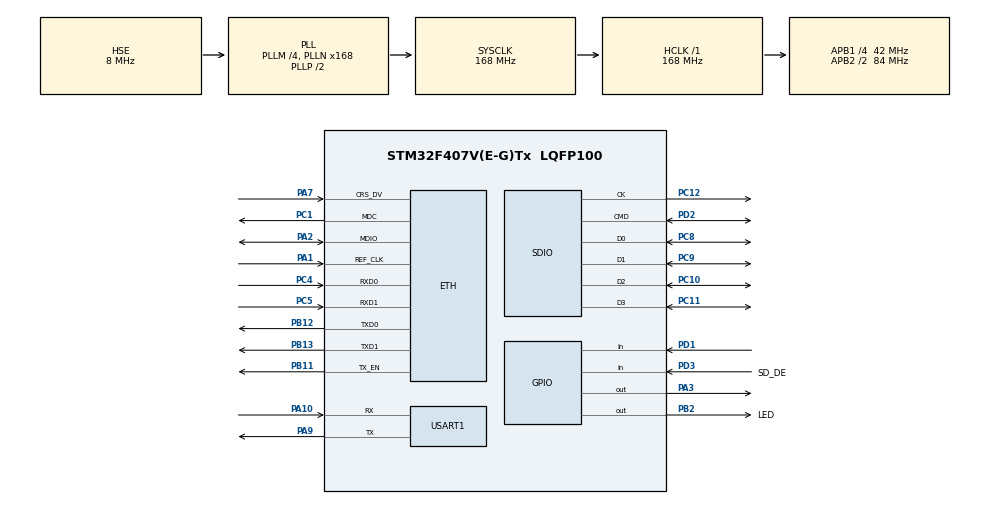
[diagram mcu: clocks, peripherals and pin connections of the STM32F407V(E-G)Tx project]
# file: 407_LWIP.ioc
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Dma.Request0=SDIO
Dma.SDIO.0.Direction=DMA_PERIPH_TO_MEMORY
Dma.SDIO.0.FIFOMode=DMA_FIFOMODE_ENABLE
Dma.SDIO.0.FIFOThreshold=DMA_FIFO_THRESHOLD_FULL
Dma.SDIO.0.Instance=DMA2_Stream3
Dma.SDIO.0.MemBurst=DMA_MBURST_INC4
Dma.SDIO.0.MemDataAlignment=DMA_MDATAALIGN_WORD
Dma.SDIO.0.MemInc=DMA_MINC_ENABLE
Dma.SDIO.0.Mode=DMA_PFCTRL
Dma.SDIO.0.PeriphBurst=DMA_PBURST_INC4
Dma.SDIO.0.PeriphDataAlignment=DMA_PDATAALIGN_WORD
Dma.SDIO.0.PeriphInc=DMA_PINC_DISABLE
Dma.SDIO.0.Priority=DMA_PRIORITY_LOW
ETH.AutoNegotiation=ETH_AUTONEGOTIATION_ENABLE
ETH.MACAddr=00\:80\:E1\:00\:00\:00
ETH.MediaInterface=ETH_MEDIA_INTERFACE_RMII
ETH.PHY_DUPLEX_STATUS=0x0010
ETH.PHY_Name_RMII=userPHY
ETH.PHY_SPEED_STATUS=0x0004
ETH.PHY_SR=0x1F
ETH.PHY_User_Name=LAN8720A
ETH.PhyAddress=0
FATFS.BSP.number=1
FATFS._CODE_PAGE=936
FATFS._USE_LFN=2
FATFS._VOLUMES=2
FATFS0.BSP.STBoard=false
FATFS0.BSP.api=Unknown
FATFS0.BSP.i2caddr=0
FATFS0.BSP.instance=PD1
FATFS0.BSP.ip=GPIO
FATFS0.BSP.mode=Input
FATFS0.BSP.name=Detect_SDIO
FATFS0.BSP.solution=PD1
FREERTOS.Tasks01=defaultTask,24,128,StartDefaultTask,Default,NULL,Dynamic,NULL,NULL
LWIP.GATEWAY_ADDRESS=192.168.001.001
LWIP.IP_ADDRESS=192.168.001.233
LWIP.LWIP_DHCP=0
LWIP.LWIP_HTTPD=0
LWIP.LWIP_NETIF_STATUS_CALLBACK=1
LWIP.NETMASK_ADDRESS=255.255.255.000
LWIP.Version=v2.1.2_Cube
Mcu.Family=STM32F4
Mcu.Name=STM32F407V(E-G)Tx
Mcu.Package=LQFP100
NVIC.DMA2_Stream3_IRQn=true\:6\:0\:true\:false\:true\:true\:false\:true
NVIC.ETH_IRQn=true\:5\:0\:false\:false\:true\:true\:false\:true
NVIC.PriorityGroup=NVIC_PRIORITYGROUP_4
NVIC.SDIO_IRQn=true\:5\:0\:false\:false\:true\:true\:true\:true
PA1.Mode=RMII
PA1.Signal=ETH_REF_CLK
PA10.Mode=Asynchronous
PA10.Signal=USART1_RX
PA13.Mode=Serial_Wire
PA13.Signal=SYS_JTMS-SWDIO
PA14.Mode=Serial_Wire
PA14.Signal=SYS_JTCK-SWCLK
PA2.Mode=RMII
PA2.Signal=ETH_MDIO
PA3.GPIO_PuPd=GPIO_PULLUP
PA3.PinState=GPIO_PIN_SET
PA3.Signal=GPIO_Output
PA7.Mode=RMII
PA7.Signal=ETH_CRS_DV
PA9.Mode=Asynchronous
PA9.Signal=USART1_TX
PB11.Mode=RMII
PB11.Signal=ETH_TX_EN
PB12.Mode=RMII
PB12.Signal=ETH_TXD0
PB13.Mode=RMII
PB13.Signal=ETH_TXD1
PB2.GPIO_Label=LED
PB2.GPIO_PuPd=GPIO_PULLUP
PB2.Signal=GPIO_Output
PC1.Mode=RMII
PC1.Signal=ETH_MDC
PC10.Mode=SD_4_bits_Wide_bus
PC10.Signal=SDIO_D2
PC11.Mode=SD_4_bits_Wide_bus
PC11.Signal=SDIO_D3
PC12.Mode=SD_4_bits_Wide_bus
PC12.Signal=SDIO_CK
PC4.Mode=RMII
PC4.Signal=ETH_RXD0
PC5.Mode=RMII
PC5.Signal=ETH_RXD1
PC8.Mode=SD_4_bits_Wide_bus
PC8.Signal=SDIO_D0
PC9.Mode=SD_4_bits_Wide_bus
PC9.Signal=SDIO_D1
PD1.Signal=GPIO_Input
PD2.Mode=SD_4_bits_Wide_bus
PD2.Signal=SDIO_CMD
PD3.GPIO_Label=SD_DE
PD3.GPIO_PuPd=GPIO_PULLUP
PD3.Signal=GPIO_Input
PH0-OSC_IN.Mode=HSE-External-Oscillator
PH0-OSC_IN.Signal=RCC_OSC_IN
PH1-OSC_OUT.Mode=HSE-External-Oscillator
PH1-OSC_OUT.Signal=RCC_OSC_OUT
ProjectManager.HeapSize=0x200
ProjectManager.StackSize=0x1000
ProjectManager.TargetToolchain=MDK-ARM V5.27
RCC.48MHZClocksFreq_Value=48000000
RCC.AHBFreq_Value=168000000
RCC.APB1CLKDivider=RCC_HCLK_DIV4
RCC.APB1Freq_Value=42000000
RCC.APB1TimFreq_Value=84000000
RCC.APB2CLKDivider=RCC_HCLK_DIV2
RCC.APB2Freq_Value=84000000
RCC.APB2TimFreq_Value=168000000
RCC.CortexFreq_Value=168000000
RCC.HCLKFreq_Value=168000000
RCC.HSE_VALUE=8000000
RCC.HSI_VALUE=16000000
RCC.LSE_VALUE=32768
RCC.PLLM=4
RCC.PLLN=168
RCC.PLLQ=7
RCC.PLLSourceVirtual=RCC_PLLSOURCE_HSE
RCC.SYSCLKFreq_VALUE=168000000
RCC.SYSCLKSource=RCC_SYSCLKSOURCE_PLLCLK
RCC.VCOOutputFreq_Value=336000000
USART1.VirtualMode=VM_ASYNC
VP_FATFS_VS_SDIO.Mode=SDIO
VP_FREERTOS_VS_CMSIS_V2.Mode=CMSIS_V2
VP_LWIP_VS_Enabled.Mode=Enabled
board=custom

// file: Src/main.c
/* USER CODE BEGIN Header */
/**
  ******************************************************************************
  * @file           : main.c
  * @brief          : Main program body
  ******************************************************************************
  * @attention
  *
  * <h2><center>&copy; Copyright (c) 2025 STMicroelectronics.
  * All rights reserved.</center></h2>
  *
  * This software component is licensed by ST under Ultimate Liberty license
  * SLA0044, the "License"; You may not use this file except in compliance with
  * the License. You may obtain a copy of the License at:
  *                             www.st.com/SLA0044
  *
  ******************************************************************************
  */
/* USER CODE END Header */
#include "main.h"
#include "cmsis_os.h"
#include "dma.h"
#include "fatfs.h"
#include "lwip.h"
#include "sdio.h"
#include "usart.h"
#include "gpio.h"

void SystemClock_Config(void);
void MX_FREERTOS_Init(void);
/* USER CODE BEGIN PFP */
extern struct netif gnetif;
struct dhcp *dhcp;
/* USER CODE END PFP */

int main(void)
{

  /* MCU Configuration--------------------------------------------------------*/

  /* Reset of all peripherals, Initializes the Flash interface and the Systick. */
  HAL_Init();

  /* Configure the system clock */
  SystemClock_Config();

  /* Initialize all configured peripherals */
  MX_GPIO_Init();
  MX_DMA_Init();
  MX_USART1_UART_Init();
  MX_SDIO_SD_Init();
  MX_FATFS_Init();
  /* USER CODE BEGIN 2 */
  HAL_GPIO_WritePin(GPIOA, GPIO_PIN_3, GPIO_PIN_RESET);
  HAL_Delay(100);
  HAL_GPIO_WritePin(GPIOA, GPIO_PIN_3, GPIO_PIN_SET);
  /* USER CODE END 2 */

  /* Init scheduler */
  osKernelInitialize();  /* Call init function for freertos objects (in freertos.c) */
  MX_FREERTOS_Init();
  /* Start scheduler */
  osKernelStart();

  /* We should never get here as control is now taken by the scheduler */
  /* Infinite loop */
  while (1)
  {

  }
}

void SystemClock_Config(void)
{
  RCC_OscInitTypeDef RCC_OscInitStruct = {0};
  RCC_ClkInitTypeDef RCC_ClkInitStruct = {0};

  /** Configure the main internal regulator output voltage
  */
  __HAL_RCC_PWR_CLK_ENABLE();
  __HAL_PWR_VOLTAGESCALING_CONFIG(PWR_REGULATOR_VOLTAGE_SCALE1);
  /** Initializes the RCC Oscillators according to the specified parameters
  * in the RCC_OscInitTypeDef structure.
  */
  RCC_OscInitStruct.OscillatorType = RCC_OSCILLATORTYPE_HSE;
  RCC_OscInitStruct.HSEState = RCC_HSE_ON;
  RCC_OscInitStruct.PLL.PLLState = RCC_PLL_ON;
  RCC_OscInitStruct.PLL.PLLSource = RCC_PLLSOURCE_HSE;
  RCC_OscInitStruct.PLL.PLLM = 4;
  RCC_OscInitStruct.PLL.PLLN = 168;
  RCC_OscInitStruct.PLL.PLLP = RCC_PLLP_DIV2;
  RCC_OscInitStruct.PLL.PLLQ = 7;
  if (HAL_RCC_OscConfig(&RCC_OscInitStruct) != HAL_OK)
  {
    Error_Handler();
  }
  /** Initializes the CPU, AHB and APB buses clocks
  */
  RCC_ClkInitStruct.ClockType = RCC_CLOCKTYPE_HCLK|RCC_CLOCKTYPE_SYSCLK
                              |RCC_CLOCKTYPE_PCLK1|RCC_CLOCKTYPE_PCLK2;
  RCC_ClkInitStruct.SYSCLKSource = RCC_SYSCLKSOURCE_PLLCLK;
  RCC_ClkInitStruct.AHBCLKDivider = RCC_SYSCLK_DIV1;
  RCC_ClkInitStruct.APB1CLKDivider = RCC_HCLK_DIV4;
  RCC_ClkInitStruct.APB2CLKDivider = RCC_HCLK_DIV2;

  if (HAL_RCC_ClockConfig(&RCC_ClkInitStruct, FLASH_LATENCY_5) != HAL_OK)
  {
    Error_Handler();
  }
}

void Error_Handler(void)
{
  __disable_irq();
  while (1)
  {
  }
}

/************************ (C) COPYRIGHT STMicroelectronics *****END OF FILE****/

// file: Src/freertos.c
/* USER CODE BEGIN Header */
/**
  ******************************************************************************
  * File Name          : freertos.c
  * Description        : Code for freertos applications
  ******************************************************************************
  * @attention
  *
  * <h2><center>&copy; Copyright (c) 2025 STMicroelectronics.
  * All rights reserved.</center></h2>
  *
  * This software component is licensed by ST under Ultimate Liberty license
  * SLA0044, the "License"; You may not use this file except in compliance with
  * the License. You may obtain a copy of the License at:
  *                             www.st.com/SLA0044
  *
  ******************************************************************************
  */
/* USER CODE END Header */

#include "FreeRTOS.h"
#include "task.h"
#include "main.h"
#include "cmsis_os.h"

/* USER CODE BEGIN Includes */
#include "lwip/sockets.h"
#include "lwip/sys.h"

#include "fatfs.h"

#include "stdio.h"
#include "string.h"

#include "httpServer.h"
/* USER CODE END Includes */

/* USER CODE BEGIN PM */
#define TCP_PORT 8080
#define MAX_BUFFER_SIZE 1024
#define MAX_CLIENTS 5  // �??????大客户端数量

#define MULTICAST_PORT_LOCAL 20001
#define MULTICAST_PORT_REMOTE 20002
#define MULTICAST_IP "226.0.0.80"

FATFS fs;                       /* FatFs 文件系统对象 */
/* USER CODE END PM */

/* Definitions for defaultTask */
osThreadId_t defaultTaskHandle;
const osThreadAttr_t defaultTask_attributes = {
  .name = "defaultTask",
  .stack_size = 128 * 4,
  .priority = (osPriority_t) osPriorityNormal,
};

/* USER CODE BEGIN FunctionPrototypes */
osThreadId_t tcpServerTaskHandle;
const osThreadAttr_t tcpServer_attributes = {
  .name = "tcpServerTask",
  .stack_size = 128 * 8,
  .priority = (osPriority_t) osPriorityBelowNormal5,
};
void StartTcpServerTask(void *argument);

osThreadId_t multicastTaskHandle;
const osThreadAttr_t multicast_attributes = {
  .name = "multicastTask",
  .stack_size = 128 * 8,
  .priority = (osPriority_t) osPriorityBelowNormal6,
};
void StartMulticastTask(void *argument);

// // SD TASK
// osThreadId_t sdTaskHandle;
// const osThreadAttr_t sdTask_attributes = {
//   .name = "sdTask",
//   .stack_size = 128 * 8,
//   .priority = (osPriority_t) osPriorityBelowNormal7,
// };
// void StartSdTask(void *argument);

// void http_request_handler(int socket, http_request_t *request);

void rainbow_handler(int socket, http_request_t *request);
void brightness_handler(int socket, http_request_t *request);
void random_handler(int socket, http_request_t *request);
void color_handler(int socket, http_request_t *request);
/* USER CODE END FunctionPrototypes */

void StartDefaultTask(void *argument);

extern void MX_LWIP_Init(void);
void MX_FREERTOS_Init(void); /* (MISRA C 2004 rule 8.1) */

void MX_FREERTOS_Init(void) {

  /* Create the thread(s) */
  /* creation of defaultTask */
  defaultTaskHandle = osThreadNew(StartDefaultTask, NULL, &defaultTask_attributes);

  /* USER CODE BEGIN RTOS_THREADS */
  /* add threads, ... */
  // tcpServerTaskHandle = osThreadNew(StartTcpServerTask, NULL, &tcpServer_attributes);
  // multicastTaskHandle = osThreadNew(StartMulticastTask, NULL, &multicast_attributes);

  // sdTaskHandle = osThreadNew(StartSdTask, NULL, &sdTask_attributes);

  // http_server_init(80);
  // // http_server_set_callback(http_request_handler);
  // http_register_route("/rainbow", rainbow_handler);
  // http_register_route("/brightness", brightness_handler);
  // http_register_route("/color", color_handler);
  // http_register_route("/random", random_handler);

  /* USER CODE END RTOS_THREADS */

}

void StartDefaultTask(void *argument)
{
  /* init code for LWIP */
  MX_LWIP_Init();
  /* USER CODE BEGIN StartDefaultTask */

  FRESULT f_res;
  f_res = f_mount(&fs, "0:", 1);
  if (f_res != FR_OK) {
    printf("Mount failed\r\n");
  } else {
    printf("Mount success\r\n");
  }

  // struct netif *netif = netif_default;

  // if (netif != NULL && netif_is_up(netif))
  // {
  //   printf("\r\nNetwork Parameters:");
  //   printf("\r\nIP Address: %s", ip4addr_ntoa(netif_ip4_addr(netif)));
  //   printf("\r\nSubnet Mask: %s", ip4addr_ntoa(netif_ip4_netmask(netif)));
  //   printf("\r\nGateway: %s", ip4addr_ntoa(netif_ip4_gw(netif)));
  //   printf("\r\nMAC Address: %02X-%02X-%02X-%02X-%02X-%02X\r\n",
  //          netif->hwaddr[0], netif->hwaddr[1], netif->hwaddr[2],
  //          netif->hwaddr[3], netif->hwaddr[4], netif->hwaddr[5]);
  // }else{
  //   printf("Network interface is down\r\n");
  // }
  /* Infinite loop */
  for(;;)
  {
    HAL_GPIO_TogglePin(LED_GPIO_Port, LED_Pin);
    // printf("Hello LWIP\r\n");
    osDelay(500);
  }
  /* USER CODE END StartDefaultTask */
}

/* USER CODE BEGIN Application */

// void StartTcpServerTask(void *argument)
// {
//   int server_fd;                       // 连接句柄
//   struct sockaddr_in server_addr, client_addr;    // 服务器和客户端地�??????
//   uint8_t rx_buffer[128];
//   socklen_t addr_len = sizeof(client_addr);

//   // 客户端管理数�??????
//   int client_sockets[MAX_CLIENTS] = {0};
//   fd_set readfds;
//   int max_sd, activity;

//   server_fd = socket(AF_INET, SOCK_STREAM, 0);    // 创建套接�??????
//   if (server_fd < 0)
//   {
//     printf("Create socket failed 1\r\n");
//     vTaskDelete(NULL);
//     return;
//   }

//   server_addr.sin_family = AF_INET;
//   server_addr.sin_port = htons(TCP_PORT);
//   server_addr.sin_addr.s_addr = INADDR_ANY;

//   if (bind(server_fd, (struct sockaddr *)&server_addr, sizeof(server_addr)) < 0)
//   {
//     printf("Bind failed\r\n");
//     vTaskDelete(NULL);
//     return;
//   }

//   if (listen(server_fd, MAX_CLIENTS) < 0)
//   {
//     printf("Socket listen failed\r\n");
//     closesocket(server_fd);
//     vTaskDelay(NULL);
//     return;
//   }
//   printf("TCP Server started on port %d\r\n", TCP_PORT);

//   while(1)
//   {

//     // 清空描述符集合并添加服务器socket
//     FD_ZERO(&readfds);
//     FD_SET(server_fd, &readfds);
//     max_sd = server_fd;

//     // 添加客户端socket到集�??????
//     for(int i = 0; i < MAX_CLIENTS; i++)
//     {
//       if(client_sockets[i] > 0)
//       {
//         FD_SET(client_sockets[i], &readfds);
//         if(client_sockets[i] > max_sd)
//           max_sd = client_sockets[i];
//       }
//     }

//     // 设置超时时间
//     struct timeval tv = {0, 10000}; // 10ms超时

//     // 等待事件发生
//     activity = select(max_sd + 1, &readfds, NULL, NULL, &tv);
//     if(activity < 0)
//     {
//       printf("Select error\r\n");
//       continue;
//     }

//     // �??????查是否有新的连接请求
//     if(FD_ISSET(server_fd, &readfds))
//     {
//       int new_socket = accept(server_fd, (struct sockaddr *)&server_addr, &addr_len);
//       if(new_socket < 0)
//       {
//         printf("Accept failed\r\n");
//         continue;
//       }

//       // 添加新的客户端socket到数�??????
//       for(int i = 0; i < MAX_CLIENTS; i++)
//       {
//         if(client_sockets[i] == 0)
//         {
//           client_sockets[i] = new_socket;
//           // 打印客户端IP地址和端�??????
//           printf("New client connected, IP: %s, Port: %d\r\n", inet_ntoa(server_addr.sin_addr), ntohs(server_addr.sin_port));
//           printf("New client connected, socket fd is %d\r\n", new_socket);
//           break;
//         }
//       }
//     }

//     // �??????查客户端数据
//     for(int i = 0; i < MAX_CLIENTS; i++)
//     {
//       if(client_sockets[i] > 0 && FD_ISSET(client_sockets[i], &readfds))
//       {
//         memset(rx_buffer, 0, sizeof(rx_buffer));
//         int rx_len = recv(client_sockets[i], rx_buffer, sizeof(rx_buffer), 0);

//         if(rx_len <= 0)
//         {
//           // 客户端断�??????连接
//           printf("Client disconnected, socket fd %d\r\n", client_sockets[i]);
//           closesocket(client_sockets[i]);
//           client_sockets[i] = 0;
//         }
//         else
//         {
//           // 处理接收到的数据
//           printf("From client %d: %s", i, rx_buffer);
//         }
//       }
//     }

//     osDelay(1);

//     // client_fd = accept(server_fd, (struct sockaddr *)&client_addr, &addr_len);
//     // if (client_fd < 0)
//     // {
//     //   printf("Socket accept failed\r\n");
//     //   continue;
//     // }

//     // printf("New client connected\r\n");

//     // while(1)
//     // {
//     //   memset(rx_buffer, 0, sizeof(rx_buffer));
//     //   int rx_len = recv(client_fd, rx_buffer, sizeof(rx_buffer), 0);
//     //   if (rx_len < 0)
//     //   {
//     //     printf("Client disconnected\r\n");
//     //     break;
//     //   }

//     //   printf("%s", rx_buffer);
//     // }
//     // closesocket(client_fd);
//   }
// }

// void StartMulticastTask(void *argument)
// {
//     int sock;
//     struct sockaddr_in local_addr, remote_addr;
//     struct ip_mreq mreq;
//     char rx_buffer[128];
//     char tx_buffer[] = "Multicast test message\r\n";

//     // 创建UDP套接�??????
//     sock = socket(AF_INET, SOCK_DGRAM, 0);
//     if (sock < 0) {
//         printf("Create multicast socket failed\r\n");
//         vTaskDelete(NULL);
//         return;
//     }

//     // 配置本地地址
//     memset(&local_addr, 0, sizeof(local_addr));
//     local_addr.sin_family = AF_INET;
//     local_addr.sin_port = htons(MULTICAST_PORT_LOCAL);
//     local_addr.sin_addr.s_addr = INADDR_ANY;

//     // 绑定socket到本地地�??????
//     if (bind(sock, (struct sockaddr*)&local_addr, sizeof(local_addr)) < 0) {
//         printf("Bind multicast socket failed\r\n");
//         closesocket(sock);
//         vTaskDelete(NULL);
//         return;
//     }

//     // 配置组播
//     mreq.imr_multiaddr.s_addr = inet_addr(MULTICAST_IP);
//     mreq.imr_interface.s_addr = INADDR_ANY;

//     // 加入组播�??????
//     if (setsockopt(sock, IPPROTO_IP, IP_ADD_MEMBERSHIP,
//                    (char *)&mreq, sizeof(mreq)) < 0) {
//         printf("Join multicast group failed\r\n");
//         closesocket(sock);
//         vTaskDelete(NULL);
//         return;
//     }

//     // 配置远程地址
//     memset(&remote_addr, 0, sizeof(remote_addr));
//     remote_addr.sin_family = AF_INET;
//     remote_addr.sin_port = htons(MULTICAST_PORT_REMOTE);
//     remote_addr.sin_addr.s_addr = inet_addr(MULTICAST_IP);

//     printf("Multicast task started\r\n");

//     while(1) {
//         fd_set readfds;
//         struct timeval tv = {0, 10000}; // 10ms超时

//         FD_ZERO(&readfds);
//         FD_SET(sock, &readfds);

//         // �??????查是否有数据可读
//         if (select(sock + 1, &readfds, NULL, NULL, &tv) > 0) {
//             if (FD_ISSET(sock, &readfds)) {
//                 // 接收数据
//                 memset(rx_buffer, 0, sizeof(rx_buffer));
//                 socklen_t addr_len = sizeof(remote_addr);
//                 int len = recvfrom(sock, rx_buffer, sizeof(rx_buffer)-1, 0,
//                                  (struct sockaddr*)&remote_addr, &addr_len);
//                 if (len > 0) {
//                     printf("Received multicast: %s\r\n", rx_buffer);
//                 }
//             }
//         }

//         // 每秒发�?�一次组播消�??????
//         static uint32_t last_send = 0;
//         uint32_t now = HAL_GetTick();
//         if (now - last_send >= 1000) {
//             sendto(sock, tx_buffer, strlen(tx_buffer), 0,
//                   (struct sockaddr*)&remote_addr, sizeof(remote_addr));
//             last_send = now;
//         }

//         osDelay(1);
//     }
// }

// void vAssertCalled(const char* file, int line)
// {
//     printf("Assert failed in %s:%d\r\n", file, line);

//     // 打印任务信息
//     TaskHandle_t currentTask = xTaskGetCurrentTaskHandle();
//     if (currentTask != NULL)
//     {
//         char *taskName = pcTaskGetName(currentTask);
//         printf("Current task: %s\r\n", taskName);

//         UBaseType_t stackHighWaterMark = uxTaskGetStackHighWaterMark(NULL);
//         printf("Stack high water mark: %lu\r\n", stackHighWaterMark);
//     }

//     // 打印�??????有任务状�??????
//     char *buffer = pvPortMalloc(2048);
//     if (buffer != NULL)
//     {
//         vTaskList(buffer);
//         printf("\r\nTask List:\r\n");
//         printf("Name          State  Priority  Stack   Num\r\n");
//         printf("*******************************************\r\n");
//         printf("%s\r\n", buffer);
//         vPortFree(buffer);
//     }
// }

void vAssertCalled(const char* file, int line)
{
    printf("Assert failed in %s:%d\r\n", file, line);

    // 打印当前任务信息
    TaskHandle_t currentTask = xTaskGetCurrentTaskHandle();
    if (currentTask != NULL)
    {
        char *taskName = pcTaskGetName(currentTask);
        printf("Current task: %s\r\n", taskName);

        // 打印堆栈使用情况
        UBaseType_t stackHighWaterMark = uxTaskGetStackHighWaterMark(NULL);
        printf("Stack high water mark: %lu words\r\n", stackHighWaterMark);
    }
    taskDISABLE_INTERRUPTS();
    for(;;);
}

// static const char index[] = {
//   0x3c, 0x21, 0x44, 0x4f, 0x43, 0x54, 0x59, 0x50, 0x45, 0x20, 0x68, 0x74, 0x6d, 0x6c, 0x3e, 0x0d,
//   0x0a, 0x3c, 0x68, 0x74, 0x6d, 0x6c, 0x3e, 0x0d, 0x0a, 0x3c, 0x68, 0x65, 0x61, 0x64, 0x3e, 0x0d,
//   0x0a, 0x20, 0x20, 0x20, 0x20, 0x3c, 0x6d, 0x65, 0x74, 0x61, 0x20, 0x63, 0x68, 0x61, 0x72, 0x73,
//   0x65, 0x74, 0x3d, 0x22, 0x55, 0x54, 0x46, 0x2d, 0x38, 0x22, 0x3e, 0x0d, 0x0a, 0x20, 0x20, 0x20,
//   0x20, 0x3c, 0x6d, 0x65, 0x74, 0x61, 0x20, 0x6e, 0x61, 0x6d, 0x65, 0x3d, 0x22, 0x76, 0x69, 0x65,
//   0x77, 0x70, 0x6f, 0x72, 0x74, 0x22, 0x20, 0x63, 0x6f, 0x6e, 0x74, 0x65, 0x6e, 0x74, 0x3d, 0x22,
//   0x77, 0x69, 0x64, 0x74, 0x68, 0x3d, 0x64, 0x65, 0x76, 0x69, 0x63, 0x65, 0x2d, 0x77, 0x69, 0x64,
//   0x74, 0x68, 0x2c, 0x20, 0x69, 0x6e, 0x69, 0x74, 0x69, 0x61, 0x6c, 0x2d, 0x73, 0x63, 0x61, 0x6c,
//   0x65, 0x3d, 0x31, 0x2e, 0x30, 0x22, 0x3e, 0x0d, 0x0a, 0x20, 0x20, 0x20, 0x20, 0x3c, 0x74, 0x69,
//   0x74, 0x6c, 0x65, 0x3e, 0x4c, 0x45, 0x44, 0xe6, 0x8e, 0xa7, 0xe5, 0x88, 0xb6, 0x3c, 0x2f, 0x74,
//   0x69, 0x74, 0x6c, 0x65, 0x3e, 0x0d, 0x0a, 0x20, 0x20, 0x20, 0x20, 0x3c, 0x73, 0x74, 0x79, 0x6c,
//   0x65, 0x3e, 0x0d, 0x0a, 0x20, 0x20, 0x20, 0x20, 0x20, 0x20, 0x20, 0x20, 0x62, 0x6f, 0x64, 0x79,
//   0x20, 0x7b, 0x20, 0x0d, 0x0a, 0x20, 0x20, 0x20, 0x20, 0x20, 0x20, 0x20, 0x20, 0x20, 0x20, 0x20,
//   0x20, 0x74, 0x65, 0x78, 0x74, 0x2d, 0x61, 0x6c, 0x69, 0x67, 0x6e, 0x3a, 0x20, 0x63, 0x65, 0x6e,
//   0x74, 0x65, 0x72, 0x3b, 0x20, 0x0d, 0x0a, 0x20, 0x20, 0x20, 0x20, 0x20, 0x20, 0x20, 0x20, 0x20,
//   0x20, 0x20, 0x20, 0x66, 0x6f, 0x6e, 0x74, 0x2d, 0x66, 0x61, 0x6d, 0x69, 0x6c, 0x79, 0x3a, 0x20,
//   0x41, 0x72, 0x69, 0x61, 0x6c, 0x3b, 0x20, 0x0d, 0x0a, 0x20, 0x20, 0x20, 0x20, 0x20, 0x20, 0x20,
//   0x20, 0x20, 0x20, 0x20, 0x20, 0x6d, 0x61, 0x78, 0x2d, 0x77, 0x69, 0x64, 0x74, 0x68, 0x3a, 0x20,
//   0x38, 0x30, 0x30, 0x70, 0x78, 0x3b, 0x0d, 0x0a, 0x20, 0x20, 0x20, 0x20, 0x20, 0x20, 0x20, 0x20,
//   0x20, 0x20, 0x20, 0x20, 0x6d, 0x61, 0x72, 0x67, 0x69, 0x6e, 0x3a, 0x20, 0x30, 0x20, 0x61, 0x75,
//   0x74, 0x6f, 0x3b, 0x0d, 0x0a, 0x20, 0x20, 0x20, 0x20, 0x20, 0x20, 0x20, 0x20, 0x20, 0x20, 0x20,
//   0x20, 0x70, 0x61, 0x64, 0x64, 0x69, 0x6e, 0x67, 0x3a, 0x20, 0x32, 0x30, 0x70, 0x78, 0x3b, 0x0d,
//   0x0a, 0x20, 0x20, 0x20, 0x20, 0x20, 0x20, 0x20, 0x20, 0x20, 0x20, 0x20, 0x20, 0x62, 0x61, 0x63,
//   0x6b, 0x67, 0x72, 0x6f, 0x75, 0x6e, 0x64, 0x2d, 0x63, 0x6f, 0x6c, 0x6f, 0x72, 0x3a, 0x20, 0x23,
//   0x66, 0x30, 0x66, 0x30, 0x66, 0x30, 0x3b, 0x0d, 0x0a, 0x20, 0x20, 0x20, 0x20, 0x20, 0x20, 0x20,
//   0x20, 0x7d, 0x0d, 0x0a, 0x20, 0x20, 0x20, 0x20, 0x20, 0x20, 0x20, 0x20, 0x2e, 0x63, 0x6f, 0x6e,
//   0x74, 0x61, 0x69, 0x6e, 0x65, 0x72, 0x20, 0x7b, 0x0d, 0x0a, 0x20, 0x20, 0x20, 0x20, 0x20, 0x20,
//   0x20, 0x20, 0x20, 0x20, 0x20, 0x20, 0x62, 0x61, 0x63, 0x6b, 0x67, 0x72, 0x6f, 0x75, 0x6e, 0x64,
//   0x2d, 0x63, 0x6f, 0x6c, 0x6f, 0x72, 0x3a, 0x20, 0x77, 0x68, 0x69, 0x74, 0x65, 0x3b, 0x0d, 0x0a,
//   0x20, 0x20, 0x20, 0x20, 0x20, 0x20, 0x20, 0x20, 0x20, 0x20, 0x20, 0x20, 0x70, 0x61, 0x64, 0x64,
//   0x69, 0x6e, 0x67, 0x3a, 0x20, 0x32, 0x30, 0x70, 0x78, 0x3b, 0x0d, 0x0a, 0x20, 0x20, 0x20, 0x20,
//   0x20, 0x20, 0x20, 0x20, 0x20, 0x20, 0x20, 0x20, 0x62, 0x6f, 0x72, 0x64, 0x65, 0x72, 0x2d, 0x72,
//   0x61, 0x64, 0x69, 0x75, 0x73, 0x3a, 0x20, 0x31, 0x30, 0x70, 0x78, 0x3b, 0x0d, 0x0a, 0x20, 0x20,
//   0x20, 0x20, 0x20, 0x20, 0x20, 0x20, 0x20, 0x20, 0x20, 0x20, 0x62, 0x6f, 0x78, 0x2d, 0x73, 0x68,
//   0x61, 0x64, 0x6f, 0x77, 0x3a, 0x20, 0x30, 0x20, 0x32, 0x70, 0x78, 0x20, 0x35, 0x70, 0x78, 0x20,
//   0x72, 0x67, 0x62, 0x61, 0x28, 0x30, 0x2c, 0x30, 0x2c, 0x30, 0x2c, 0x30, 0x2e, 0x31, 0x29, 0x3b,
//   0x0d, 0x0a, 0x20, 0x20, 0x20, 0x20, 0x20, 0x20, 0x20, 0x20, 0x7d, 0x0d, 0x0a, 0x20, 0x20, 0x20,
//   0x20, 0x20, 0x20, 0x20, 0x20, 0x2e, 0x63, 0x6f, 0x6c, 0x6f, 0x72, 0x50, 0x69, 0x63, 0x6b, 0x65,
//   0x72, 0x20, 0x7b, 0x20, 0x0d, 0x0a, 0x20, 0x20, 0x20, 0x20, 0x20, 0x20, 0x20, 0x20, 0x20, 0x20,
//   0x20, 0x20, 0x6d, 0x61, 0x72, 0x67, 0x69, 0x6e, 0x3a, 0x20, 0x32, 0x30, 0x70, 0x78, 0x3b, 0x0d,
//   0x0a, 0x20, 0x20, 0x20, 0x20, 0x20, 0x20, 0x20, 0x20, 0x20, 0x20, 0x20, 0x20, 0x77, 0x69, 0x64,
//   0x74, 0x68, 0x3a, 0x20, 0x31, 0x30, 0x30, 0x70, 0x78, 0x3b, 0x0d, 0x0a, 0x20, 0x20, 0x20, 0x20,
//   0x20, 0x20, 0x20, 0x20, 0x20, 0x20, 0x20, 0x20, 0x68, 0x65, 0x69, 0x67, 0x68, 0x74, 0x3a, 0x20,
//   0x35, 0x30, 0x70, 0x78, 0x3b, 0x0d, 0x0a, 0x20, 0x20, 0x20, 0x20, 0x20, 0x20, 0x20, 0x20, 0x7d,
//   0x0d, 0x0a, 0x20, 0x20, 0x20, 0x20, 0x20, 0x20, 0x20, 0x20, 0x2e, 0x62, 0x72, 0x69, 0x67, 0x68,
//   0x74, 0x6e, 0x65, 0x73, 0x73, 0x2d, 0x63, 0x6f, 0x6e, 0x74, 0x72, 0x6f, 0x6c, 0x20, 0x7b, 0x0d,
//   0x0a, 0x20, 0x20, 0x20, 0x20, 0x20, 0x20, 0x20, 0x20, 0x20, 0x20, 0x20, 0x20, 0x6d, 0x61, 0x72,
//   0x67, 0x69, 0x6e, 0x3a, 0x20, 0x32, 0x30, 0x70, 0x78, 0x3b, 0x0d, 0x0a, 0x20, 0x20, 0x20, 0x20,
//   0x20, 0x20, 0x20, 0x20, 0x20, 0x20, 0x20, 0x20, 0x77, 0x69, 0x64, 0x74, 0x68, 0x3a, 0x20, 0x38,
//   0x30, 0x25, 0x3b, 0x0d, 0x0a, 0x20, 0x20, 0x20, 0x20, 0x20, 0x20, 0x20, 0x20, 0x20, 0x20, 0x20,
//   0x20, 0x6d, 0x61, 0x78, 0x2d, 0x77, 0x69, 0x64, 0x74, 0x68, 0x3a, 0x20, 0x33, 0x30, 0x30, 0x70,
//   0x78, 0x3b, 0x0d, 0x0a, 0x20, 0x20, 0x20, 0x20, 0x20, 0x20, 0x20, 0x20, 0x20, 0x20, 0x20, 0x20,
//   0x64, 0x69, 0x73, 0x70, 0x6c, 0x61, 0x79, 0x3a, 0x20, 0x69, 0x6e, 0x6c, 0x69, 0x6e, 0x65, 0x2d,
//   0x62, 0x6c, 0x6f, 0x63, 0x6b, 0x3b, 0x0d, 0x0a, 0x20, 0x20, 0x20, 0x20, 0x20, 0x20, 0x20, 0x20,
//   0x7d, 0x0d, 0x0a, 0x20, 0x20, 0x20, 0x20, 0x20, 0x20, 0x20, 0x20, 0x2e, 0x73, 0x6c, 0x69, 0x64,
//   0x65, 0x72, 0x20, 0x7b, 0x0d, 0x0a, 0x20, 0x20, 0x20, 0x20, 0x20, 0x20, 0x20, 0x20, 0x20, 0x20,
//   0x20, 0x20, 0x77, 0x69, 0x64, 0x74, 0x68, 0x3a, 0x20, 0x31, 0x30, 0x30, 0x25, 0x3b, 0x0d, 0x0a,
//   0x20, 0x20, 0x20, 0x20, 0x20, 0x20, 0x20, 0x20, 0x20, 0x20, 0x20, 0x20, 0x68, 0x65, 0x69, 0x67,
//   0x68, 0x74, 0x3a, 0x20, 0x32, 0x35, 0x70, 0x78, 0x3b, 0x0d, 0x0a, 0x20, 0x20, 0x20, 0x20, 0x20,
//   0x20, 0x20, 0x20, 0x20, 0x20, 0x20, 0x20, 0x6d, 0x61, 0x72, 0x67, 0x69, 0x6e, 0x3a, 0x20, 0x31,
//   0x30, 0x70, 0x78, 0x20, 0x30, 0x3b, 0x0d, 0x0a, 0x20, 0x20, 0x20, 0x20, 0x20, 0x20, 0x20, 0x20,
//   0x7d, 0x0d, 0x0a, 0x20, 0x20, 0x20, 0x20, 0x20, 0x20, 0x20, 0x20, 0x62, 0x75, 0x74, 0x74, 0x6f,
//   0x6e, 0x20, 0x7b, 0x20, 0x0d, 0x0a, 0x20, 0x20, 0x20, 0x20, 0x20, 0x20, 0x20, 0x20, 0x20, 0x20,
//   0x20, 0x20, 0x70, 0x61, 0x64, 0x64, 0x69, 0x6e, 0x67, 0x3a, 0x20, 0x31, 0x32, 0x70, 0x78, 0x20,
//   0x32, 0x34, 0x70, 0x78, 0x3b, 0x0d, 0x0a, 0x20, 0x20, 0x20, 0x20, 0x20, 0x20, 0x20, 0x20, 0x20,
//   0x20, 0x20, 0x20, 0x6d, 0x61, 0x72, 0x67, 0x69, 0x6e, 0x3a, 0x20, 0x38, 0x70, 0x78, 0x3b, 0x0d,
//   0x0a, 0x20, 0x20, 0x20, 0x20, 0x20, 0x20, 0x20, 0x20, 0x20, 0x20, 0x20, 0x20, 0x62, 0x6f, 0x72,
//   0x64, 0x65, 0x72, 0x3a, 0x20, 0x6e, 0x6f, 0x6e, 0x65, 0x3b, 0x0d, 0x0a, 0x20, 0x20, 0x20, 0x20,
//   0x20, 0x20, 0x20, 0x20, 0x20, 0x20, 0x20, 0x20, 0x62, 0x6f, 0x72, 0x64, 0x65, 0x72, 0x2d, 0x72,
//   0x61, 0x64, 0x69, 0x75, 0x73, 0x3a, 0x20, 0x35, 0x70, 0x78, 0x3b, 0x0d, 0x0a, 0x20, 0x20, 0x20,
//   0x20, 0x20, 0x20, 0x20, 0x20, 0x20, 0x20, 0x20, 0x20, 0x63, 0x75, 0x72, 0x73, 0x6f, 0x72, 0x3a,
//   0x20, 0x70, 0x6f, 0x69, 0x6e, 0x74, 0x65, 0x72, 0x3b, 0x0d, 0x0a, 0x20, 0x20, 0x20, 0x20, 0x20,
//   0x20, 0x20, 0x20, 0x20, 0x20, 0x20, 0x20, 0x66, 0x6f, 0x6e, 0x74, 0x2d, 0x73, 0x69, 0x7a, 0x65,
//   0x3a, 0x20, 0x31, 0x36, 0x70, 0x78, 0x3b, 0x0d, 0x0a, 0x20, 0x20, 0x20, 0x20, 0x20, 0x20, 0x20,
//   0x20, 0x20, 0x20, 0x20, 0x20, 0x74, 0x72, 0x61, 0x6e, 0x73, 0x69, 0x74, 0x69, 0x6f, 0x6e, 0x3a,
//   0x20, 0x61, 0x6c, 0x6c, 0x20, 0x30, 0x2e, 0x33, 0x73, 0x20, 0x65, 0x61, 0x73, 0x65, 0x3b, 0x0d,
//   0x0a, 0x20, 0x20, 0x20, 0x20, 0x20, 0x20, 0x20, 0x20, 0x7d, 0x0d, 0x0a, 0x20, 0x20, 0x20, 0x20,
//   0x20, 0x20, 0x20, 0x20, 0x62, 0x75, 0x74, 0x74, 0x6f, 0x6e, 0x3a, 0x68, 0x6f, 0x76, 0x65, 0x72,
//   0x20, 0x7b, 0x0d, 0x0a, 0x20, 0x20, 0x20, 0x20, 0x20, 0x20, 0x20, 0x20, 0x20, 0x20, 0x20, 0x20,
//   0x74, 0x72, 0x61, 0x6e, 0x73, 0x66, 0x6f, 0x72, 0x6d, 0x3a, 0x20, 0x73, 0x63, 0x61, 0x6c, 0x65,
//   0x28, 0x31, 0x2e, 0x30, 0x35, 0x29, 0x3b, 0x0d, 0x0a, 0x20, 0x20, 0x20, 0x20, 0x20, 0x20, 0x20,
//   0x20, 0x7d, 0x0d, 0x0a, 0x20, 0x20, 0x20, 0x20, 0x20, 0x20, 0x20, 0x20, 0x2e, 0x62, 0x74, 0x6e,
//   0x2d, 0x63, 0x6f, 0x6c, 0x6f, 0x72, 0x20, 0x7b, 0x20, 0x62, 0x61, 0x63, 0x6b, 0x67, 0x72, 0x6f,
//   0x75, 0x6e, 0x64, 0x2d, 0x63, 0x6f, 0x6c, 0x6f, 0x72, 0x3a, 0x20, 0x23, 0x34, 0x43, 0x41, 0x46,
//   0x35, 0x30, 0x3b, 0x20, 0x63, 0x6f, 0x6c, 0x6f, 0x72, 0x3a, 0x20, 0x77, 0x68, 0x69, 0x74, 0x65,
//   0x3b, 0x20, 0x7d, 0x0d, 0x0a, 0x20, 0x20, 0x20, 0x20, 0x20, 0x20, 0x20, 0x20, 0x2e, 0x62, 0x74,
//   0x6e, 0x2d, 0x72, 0x61, 0x69, 0x6e, 0x62, 0x6f, 0x77, 0x20, 0x7b, 0x20, 0x62, 0x61, 0x63, 0x6b,
//   0x67, 0x72, 0x6f, 0x75, 0x6e, 0x64, 0x2d, 0x63, 0x6f, 0x6c, 0x6f, 0x72, 0x3a, 0x20, 0x23, 0x32,
//   0x31, 0x39, 0x36, 0x46, 0x33, 0x3b, 0x20, 0x63, 0x6f, 0x6c, 0x6f, 0x72, 0x3a, 0x20, 0x77, 0x68,
//   0x69, 0x74, 0x65, 0x3b, 0x20, 0x7d, 0x0d, 0x0a, 0x20, 0x20, 0x20, 0x20, 0x20, 0x20, 0x20, 0x20,
//   0x2e, 0x62, 0x74, 0x6e, 0x2d, 0x72, 0x61, 0x6e, 0x64, 0x6f, 0x6d, 0x20, 0x7b, 0x20, 0x62, 0x61,
//   0x63, 0x6b, 0x67, 0x72, 0x6f, 0x75, 0x6e, 0x64, 0x2d, 0x63, 0x6f, 0x6c, 0x6f, 0x72, 0x3a, 0x20,
//   0x23, 0x66, 0x34, 0x34, 0x33, 0x33, 0x36, 0x3b, 0x20, 0x63, 0x6f, 0x6c, 0x6f, 0x72, 0x3a, 0x20,
//   0x77, 0x68, 0x69, 0x74, 0x65, 0x3b, 0x20, 0x7d, 0x0d, 0x0a, 0x20, 0x20, 0x20, 0x20, 0x20, 0x20,
//   0x20, 0x20, 0x2e, 0x73, 0x74, 0x61, 0x74, 0x75, 0x73, 0x20, 0x7b, 0x0d, 0x0a, 0x20, 0x20, 0x20,
//   0x20, 0x20, 0x20, 0x20, 0x20, 0x20, 0x20, 0x20, 0x20, 0x6d, 0x61, 0x72, 0x67, 0x69, 0x6e, 0x2d,
//   0x74, 0x6f, 0x70, 0x3a, 0x20, 0x32, 0x30, 0x70, 0x78, 0x3b, 0x0d, 0x0a, 0x20, 0x20, 0x20, 0x20,
//   0x20, 0x20, 0x20, 0x20, 0x20, 0x20, 0x20, 0x20, 0x70, 0x61, 0x64, 0x64, 0x69, 0x6e, 0x67, 0x3a,
//   0x20, 0x31, 0x30, 0x70, 0x78, 0x3b, 0x0d, 0x0a, 0x20, 0x20, 0x20, 0x20, 0x20, 0x20, 0x20, 0x20,
//   0x20, 0x20, 0x20, 0x20, 0x62, 0x6f, 0x72, 0x64, 0x65, 0x72, 0x2d, 0x72, 0x61, 0x64, 0x69, 0x75,
//   0x73, 0x3a, 0x20, 0x35, 0x70, 0x78, 0x3b, 0x0d, 0x0a, 0x20, 0x20, 0x20, 0x20, 0x20, 0x20, 0x20,
//   0x20, 0x20, 0x20, 0x20, 0x20, 0x62, 0x61, 0x63, 0x6b, 0x67, 0x72, 0x6f, 0x75, 0x6e, 0x64, 0x2d,
//   0x63, 0x6f, 0x6c, 0x6f, 0x72, 0x3a, 0x20, 0x23, 0x65, 0x38, 0x66, 0x35, 0x65, 0x39, 0x3b, 0x0d,
//   0x0a, 0x20, 0x20, 0x20, 0x20, 0x20, 0x20, 0x20, 0x20, 0x7d, 0x0d, 0x0a, 0x20, 0x20, 0x20, 0x20,
//   0x3c, 0x2f, 0x73, 0x74, 0x79, 0x6c, 0x65, 0x3e, 0x0d, 0x0a, 0x3c, 0x2f, 0x68, 0x65, 0x61, 0x64,
//   0x3e, 0x0d, 0x0a, 0x3c, 0x62, 0x6f, 0x64, 0x79, 0x3e, 0x0d, 0x0a, 0x20, 0x20, 0x20, 0x20, 0x3c,
//   0x64, 0x69, 0x76, 0x20, 0x63, 0x6c, 0x61, 0x73, 0x73, 0x3d, 0x22, 0x63, 0x6f, 0x6e, 0x74, 0x61,
//   0x69, 0x6e, 0x65, 0x72, 0x22, 0x3e, 0x0d, 0x0a, 0x20, 0x20, 0x20, 0x20, 0x20, 0x20, 0x20, 0x20,
//   0x3c, 0x68, 0x31, 0x3e, 0x4c, 0x45, 0x44, 0xe7, 0x81, 0xaf, 0xe5, 0xb8, 0xa6, 0xe6, 0x8e, 0xa7,
//   0xe5, 0x88, 0xb6, 0xe9, 0x9d, 0xa2, 0xe6, 0x9d, 0xbf, 0x3c, 0x2f, 0x68, 0x31, 0x3e, 0x0d, 0x0a,
//   0x20, 0x20, 0x20, 0x20, 0x20, 0x20, 0x20, 0x20, 0x0d, 0x0a, 0x20, 0x20, 0x20, 0x20, 0x20, 0x20,
//   0x20, 0x20, 0x3c, 0x64, 0x69, 0x76, 0x20, 0x63, 0x6c, 0x61, 0x73, 0x73, 0x3d, 0x22, 0x62, 0x72,
//   0x69, 0x67, 0x68, 0x74, 0x6e, 0x65, 0x73, 0x73, 0x2d, 0x63, 0x6f, 0x6e, 0x74, 0x72, 0x6f, 0x6c,
//   0x22, 0x3e, 0x0d, 0x0a, 0x20, 0x20, 0x20, 0x20, 0x20, 0x20, 0x20, 0x20, 0x20, 0x20, 0x20, 0x20,
//   0x3c, 0x6c, 0x61, 0x62, 0x65, 0x6c, 0x3e, 0xe4, 0xba, 0xae, 0xe5, 0xba, 0xa6, 0xe6, 0x8e, 0xa7,
//   0xe5, 0x88, 0xb6, 0x3a, 0x20, 0x3c, 0x73, 0x70, 0x61, 0x6e, 0x20, 0x69, 0x64, 0x3d, 0x22, 0x62,
//   0x72, 0x69, 0x67, 0x68, 0x74, 0x6e, 0x65, 0x73, 0x73, 0x56, 0x61, 0x6c, 0x75, 0x65, 0x22, 0x3e,
//   0x35, 0x30, 0x3c, 0x2f, 0x73, 0x70, 0x61, 0x6e, 0x3e, 0x25, 0x3c, 0x2f, 0x6c, 0x61, 0x62, 0x65,
//   0x6c, 0x3e, 0x0d, 0x0a, 0x20, 0x20, 0x20, 0x20, 0x20, 0x20, 0x20, 0x20, 0x20, 0x20, 0x20, 0x20,
//   0x3c, 0x69, 0x6e, 0x70, 0x75, 0x74, 0x20, 0x74, 0x79, 0x70, 0x65, 0x3d, 0x22, 0x72, 0x61, 0x6e,
//   0x67, 0x65, 0x22, 0x20, 0x69, 0x64, 0x3d, 0x22, 0x62, 0x72, 0x69, 0x67, 0x68, 0x74, 0x6e, 0x65,
//   0x73, 0x73, 0x22, 0x20, 0x63, 0x6c, 0x61, 0x73, 0x73, 0x3d, 0x22, 0x73, 0x6c, 0x69, 0x64, 0x65,
//   0x72, 0x22, 0x20, 0x0d, 0x0a, 0x20, 0x20, 0x20, 0x20, 0x20, 0x20, 0x20, 0x20, 0x20, 0x20, 0x20,
//   0x20, 0x20, 0x20, 0x20, 0x20, 0x20, 0x20, 0x20, 0x6d, 0x69, 0x6e, 0x3d, 0x22, 0x30, 0x22, 0x20,
//   0x6d, 0x61, 0x78, 0x3d, 0x22, 0x32, 0x35, 0x35, 0x22, 0x20, 0x76, 0x61, 0x6c, 0x75, 0x65, 0x3d,
//   0x22, 0x31, 0x32, 0x37, 0x22, 0x0d, 0x0a, 0x20, 0x20, 0x20, 0x20, 0x20, 0x20, 0x20, 0x20, 0x20,
//   0x20, 0x20, 0x20, 0x20, 0x20, 0x20, 0x20, 0x20, 0x20, 0x20, 0x6f, 0x6e, 0x69, 0x6e, 0x70, 0x75,
//   0x74, 0x3d, 0x22, 0x75, 0x70, 0x64, 0x61, 0x74, 0x65, 0x42, 0x72, 0x69, 0x67, 0x68, 0x74, 0x6e,
//   0x65, 0x73, 0x73, 0x28, 0x74, 0x68, 0x69, 0x73, 0x2e, 0x76, 0x61, 0x6c, 0x75, 0x65, 0x29, 0x22,
//   0x3e, 0x0d, 0x0a, 0x20, 0x20, 0x20, 0x20, 0x20, 0x20, 0x20, 0x20, 0x3c, 0x2f, 0x64, 0x69, 0x76,
//   0x3e, 0x0d, 0x0a, 0x20, 0x20, 0x20, 0x20, 0x20, 0x20, 0x20, 0x20, 0x0d, 0x0a, 0x20, 0x20, 0x20,
//   0x20, 0x20, 0x20, 0x20, 0x20, 0x3c, 0x64, 0x69, 0x76, 0x3e, 0x0d, 0x0a, 0x20, 0x20, 0x20, 0x20,
//   0x20, 0x20, 0x20, 0x20, 0x20, 0x20, 0x20, 0x20, 0x3c, 0x6c, 0x61, 0x62, 0x65, 0x6c, 0x3e, 0xe9,
//   0xa2, 0x9c, 0xe8, 0x89, 0xb2, 0xe9, 0x80, 0x89, 0xe6, 0x8b, 0xa9, 0x3a, 0x3c, 0x2f, 0x6c, 0x61,
//   0x62, 0x65, 0x6c, 0x3e, 0x3c, 0x62, 0x72, 0x3e, 0x0d, 0x0a, 0x20, 0x20, 0x20, 0x20, 0x20, 0x20,
//   0x20, 0x20, 0x20, 0x20, 0x20, 0x20, 0x3c, 0x69, 0x6e, 0x70, 0x75, 0x74, 0x20, 0x74, 0x79, 0x70,
//   0x65, 0x3d, 0x22, 0x63, 0x6f, 0x6c, 0x6f, 0x72, 0x22, 0x20, 0x69, 0x64, 0x3d, 0x22, 0x63, 0x6f,
//   0x6c, 0x6f, 0x72, 0x50, 0x69, 0x63, 0x6b, 0x65, 0x72, 0x22, 0x20, 0x63, 0x6c, 0x61, 0x73, 0x73,
//   0x3d, 0x22, 0x63, 0x6f, 0x6c, 0x6f, 0x72, 0x50, 0x69, 0x63, 0x6b, 0x65, 0x72, 0x22, 0x20, 0x76,
//   0x61, 0x6c, 0x75, 0x65, 0x3d, 0x22, 0x23, 0x66, 0x66, 0x30, 0x30, 0x30, 0x30, 0x22, 0x3e, 0x0d,
//   0x0a, 0x20, 0x20, 0x20, 0x20, 0x20, 0x20, 0x20, 0x20, 0x3c, 0x2f, 0x64, 0x69, 0x76, 0x3e, 0x0d,
//   0x0a, 0x20, 0x20, 0x20, 0x20, 0x20, 0x20, 0x20, 0x20, 0x0d, 0x0a, 0x20, 0x20, 0x20, 0x20, 0x20,
//   0x20, 0x20, 0x20, 0x3c, 0x64, 0x69, 0x76, 0x3e, 0x0d, 0x0a, 0x20, 0x20, 0x20, 0x20, 0x20, 0x20,
//   0x20, 0x20, 0x20, 0x20, 0x20, 0x20, 0x3c, 0x62, 0x75, 0x74, 0x74, 0x6f, 0x6e, 0x20, 0x63, 0x6c,
//   0x61, 0x73, 0x73, 0x3d, 0x22, 0x62, 0x74, 0x6e, 0x2d, 0x63, 0x6f, 0x6c, 0x6f, 0x72, 0x22, 0x20,
//   0x6f, 0x6e, 0x63, 0x6c, 0x69, 0x63, 0x6b, 0x3d, 0x22, 0x73, 0x65, 0x74, 0x43, 0x6f, 0x6c, 0x6f,
//   0x72, 0x28, 0x29, 0x22, 0x3e, 0xe8, 0xae, 0xbe, 0xe7, 0xbd, 0xae, 0xe9, 0xa2, 0x9c, 0xe8, 0x89,
//   0xb2, 0x3c, 0x2f, 0x62, 0x75, 0x74, 0x74, 0x6f, 0x6e, 0x3e, 0x0d, 0x0a, 0x20, 0x20, 0x20, 0x20,
//   0x20, 0x20, 0x20, 0x20, 0x20, 0x20, 0x20, 0x20, 0x3c, 0x62, 0x75, 0x74, 0x74, 0x6f, 0x6e, 0x20,
//   0x63, 0x6c, 0x61, 0x73, 0x73, 0x3d, 0x22, 0x62, 0x74, 0x6e, 0x2d, 0x72, 0x61, 0x69, 0x6e, 0x62,
//   0x6f, 0x77, 0x22, 0x20, 0x6f, 0x6e, 0x63, 0x6c, 0x69, 0x63, 0x6b, 0x3d, 0x22, 0x73, 0x74, 0x61,
//   0x72, 0x74, 0x52, 0x61, 0x69, 0x6e, 0x62, 0x6f, 0x77, 0x28, 0x29, 0x22, 0x3e, 0xe5, 0xbd, 0xa9,
//   0xe8, 0x99, 0xb9, 0xe6, 0xa8, 0xa1, 0xe5, 0xbc, 0x8f, 0x3c, 0x2f, 0x62, 0x75, 0x74, 0x74, 0x6f,
//   0x6e, 0x3e, 0x0d, 0x0a, 0x20, 0x20, 0x20, 0x20, 0x20, 0x20, 0x20, 0x20, 0x20, 0x20, 0x20, 0x20,
//   0x3c, 0x62, 0x75, 0x74, 0x74, 0x6f, 0x6e, 0x20, 0x63, 0x6c, 0x61, 0x73, 0x73, 0x3d, 0x22, 0x62,
//   0x74, 0x6e, 0x2d, 0x72, 0x61, 0x6e, 0x64, 0x6f, 0x6d, 0x22, 0x20, 0x6f, 0x6e, 0x63, 0x6c, 0x69,
//   0x63, 0x6b, 0x3d, 0x22, 0x73, 0x65, 0x74, 0x52, 0x61, 0x6e, 0x64, 0x6f, 0x6d, 0x28, 0x29, 0x22,
//   0x3e, 0xe9, 0x9a, 0x8f, 0xe6, 0x9c, 0xba, 0xe9, 0xa2, 0x9c, 0xe8, 0x89, 0xb2, 0x3c, 0x2f, 0x62,
//   0x75, 0x74, 0x74, 0x6f, 0x6e, 0x3e, 0x0d, 0x0a, 0x20, 0x20, 0x20, 0x20, 0x20, 0x20, 0x20, 0x20,
//   0x3c, 0x2f, 0x64, 0x69, 0x76, 0x3e, 0x0d, 0x0a, 0x20, 0x20, 0x20, 0x20, 0x20, 0x20, 0x20, 0x20,
//   0x0d, 0x0a, 0x20, 0x20, 0x20, 0x20, 0x20, 0x20, 0x20, 0x20, 0x3c, 0x64, 0x69, 0x76, 0x20, 0x63,
//   0x6c, 0x61, 0x73, 0x73, 0x3d, 0x22, 0x73, 0x74, 0x61, 0x74, 0x75, 0x73, 0x22, 0x20, 0x69, 0x64,
//   0x3d, 0x22, 0x73, 0x74, 0x61, 0x74, 0x75, 0x73, 0x22, 0x3e, 0x3c, 0x2f, 0x64, 0x69, 0x76, 0x3e,
//   0x0d, 0x0a, 0x20, 0x20, 0x20, 0x20, 0x3c, 0x2f, 0x64, 0x69, 0x76, 0x3e, 0x0d, 0x0a, 0x0d, 0x0a,
//   0x20, 0x20, 0x20, 0x20, 0x3c, 0x73, 0x63, 0x72, 0x69, 0x70, 0x74, 0x3e, 0x0d, 0x0a, 0x20, 0x20,
//   0x20, 0x20, 0x20, 0x20, 0x20, 0x20, 0x66, 0x75, 0x6e, 0x63, 0x74, 0x69, 0x6f, 0x6e, 0x20, 0x75,
//   0x70, 0x64, 0x61, 0x74, 0x65, 0x42, 0x72, 0x69, 0x67, 0x68, 0x74, 0x6e, 0x65, 0x73, 0x73, 0x28,
//   0x76, 0x61, 0x6c, 0x75, 0x65, 0x29, 0x20, 0x7b, 0x0d, 0x0a, 0x20, 0x20, 0x20, 0x20, 0x20, 0x20,
//   0x20, 0x20, 0x20, 0x20, 0x20, 0x20, 0x64, 0x6f, 0x63, 0x75, 0x6d, 0x65, 0x6e, 0x74, 0x2e, 0x67,
//   0x65, 0x74, 0x45, 0x6c, 0x65, 0x6d, 0x65, 0x6e, 0x74, 0x42, 0x79, 0x49, 0x64, 0x28, 0x27, 0x62,
//   0x72, 0x69, 0x67, 0x68, 0x74, 0x6e, 0x65, 0x73, 0x73, 0x56, 0x61, 0x6c, 0x75, 0x65, 0x27, 0x29,
//   0x2e, 0x74, 0x65, 0x78, 0x74, 0x43, 0x6f, 0x6e, 0x74, 0x65, 0x6e, 0x74, 0x20, 0x3d, 0x20, 0x4d,
//   0x61, 0x74, 0x68, 0x2e, 0x72, 0x6f, 0x75, 0x6e, 0x64, 0x28, 0x76, 0x61, 0x6c, 0x75, 0x65, 0x20,
//   0x2f, 0x20, 0x32, 0x2e, 0x35, 0x35, 0x29, 0x3b, 0x0d, 0x0a, 0x20, 0x20, 0x20, 0x20, 0x20, 0x20,
//   0x20, 0x20, 0x20, 0x20, 0x20, 0x20, 0x66, 0x65, 0x74, 0x63, 0x68, 0x28, 0x27, 0x2f, 0x62, 0x72,
//   0x69, 0x67, 0x68, 0x74, 0x6e, 0x65, 0x73, 0x73, 0x3f, 0x76, 0x61, 0x6c, 0x75, 0x65, 0x3d, 0x27,
//   0x20, 0x2b, 0x20, 0x76, 0x61, 0x6c, 0x75, 0x65, 0x29, 0x0d, 0x0a, 0x20, 0x20, 0x20, 0x20, 0x20,
//   0x20, 0x20, 0x20, 0x20, 0x20, 0x20, 0x20, 0x20, 0x20, 0x20, 0x20, 0x2e, 0x74, 0x68, 0x65, 0x6e,
//   0x28, 0x72, 0x65, 0x73, 0x70, 0x6f, 0x6e, 0x73, 0x65, 0x20, 0x3d, 0x3e, 0x20, 0x7b, 0x0d, 0x0a,
//   0x20, 0x20, 0x20, 0x20, 0x20, 0x20, 0x20, 0x20, 0x20, 0x20, 0x20, 0x20, 0x20, 0x20, 0x20, 0x20,
//   0x20, 0x20, 0x20, 0x20, 0x69, 0x66, 0x28, 0x21, 0x72, 0x65, 0x73, 0x70, 0x6f, 0x6e, 0x73, 0x65,
//   0x2e, 0x6f, 0x6b, 0x29, 0x20, 0x74, 0x68, 0x72, 0x6f, 0x77, 0x20, 0x6e, 0x65, 0x77, 0x20, 0x45,
//   0x72, 0x72, 0x6f, 0x72, 0x28, 0x27, 0xe8, 0xae, 0xbe, 0xe7, 0xbd, 0xae, 0xe4, 0xba, 0xae, 0xe5,
//   0xba, 0xa6, 0xe5, 0xa4, 0xb1, 0xe8, 0xb4, 0xa5, 0x27, 0x29, 0x3b, 0x0d, 0x0a, 0x20, 0x20, 0x20,
//   0x20, 0x20, 0x20, 0x20, 0x20, 0x20, 0x20, 0x20, 0x20, 0x20, 0x20, 0x20, 0x20, 0x20, 0x20, 0x20,
//   0x20, 0x73, 0x68, 0x6f, 0x77, 0x53, 0x74, 0x61, 0x74, 0x75, 0x73, 0x28, 0x27, 0xe4, 0xba, 0xae,
//   0xe5, 0xba, 0xa6, 0xe5, 0xb7, 0xb2, 0xe6, 0x9b, 0xb4, 0xe6, 0x96, 0xb0, 0x27, 0x29, 0x3b, 0x0d,
//   0x0a, 0x20, 0x20, 0x20, 0x20, 0x20, 0x20, 0x20, 0x20, 0x20, 0x20, 0x20, 0x20, 0x20, 0x20, 0x20,
//   0x20, 0x7d, 0x29, 0x0d, 0x0a, 0x20, 0x20, 0x20, 0x20, 0x20, 0x20, 0x20, 0x20, 0x20, 0x20, 0x20,
//   0x20, 0x20, 0x20, 0x20, 0x20, 0x2e, 0x63, 0x61, 0x74, 0x63, 0x68, 0x28, 0x65, 0x72, 0x72, 0x6f,
//   0x72, 0x20, 0x3d, 0x3e, 0x20, 0x73, 0x68, 0x6f, 0x77, 0x53, 0x74, 0x61, 0x74, 0x75, 0x73, 0x28,
//   0x27, 0xe9, 0x94, 0x99, 0xe8, 0xaf, 0xaf, 0x3a, 0x20, 0x27, 0x20, 0x2b, 0x20, 0x65, 0x72, 0x72,
//   0x6f, 0x72, 0x2e, 0x6d, 0x65, 0x73, 0x73, 0x61, 0x67, 0x65, 0x29, 0x29, 0x3b, 0x0d, 0x0a, 0x20,
//   0x20, 0x20, 0x20, 0x20, 0x20, 0x20, 0x20, 0x7d, 0x0d, 0x0a, 0x0d, 0x0a, 0x20, 0x20, 0x20, 0x20,
//   0x20, 0x20, 0x20, 0x20, 0x66, 0x75, 0x6e, 0x63, 0x74, 0x69, 0x6f, 0x6e, 0x20, 0x73, 0x65, 0x74,
//   0x43, 0x6f, 0x6c, 0x6f, 0x72, 0x28, 0x29, 0x20, 0x7b, 0x0d, 0x0a, 0x20, 0x20, 0x20, 0x20, 0x20,
//   0x20, 0x20, 0x20, 0x20, 0x20, 0x20, 0x20, 0x76, 0x61, 0x72, 0x20, 0x63, 0x6f, 0x6c, 0x6f, 0x72,
//   0x20, 0x3d, 0x20, 0x64, 0x6f, 0x63, 0x75, 0x6d, 0x65, 0x6e, 0x74, 0x2e, 0x67, 0x65, 0x74, 0x45,
//   0x6c, 0x65, 0x6d, 0x65, 0x6e, 0x74, 0x42, 0x79, 0x49, 0x64, 0x28, 0x27, 0x63, 0x6f, 0x6c, 0x6f,
//   0x72, 0x50, 0x69, 0x63, 0x6b, 0x65, 0x72, 0x27, 0x29, 0x2e, 0x76, 0x61, 0x6c, 0x75, 0x65, 0x3b,
//   0x0d, 0x0a, 0x20, 0x20, 0x20, 0x20, 0x20, 0x20, 0x20, 0x20, 0x20, 0x20, 0x20, 0x20, 0x76, 0x61,
//   0x72, 0x20, 0x72, 0x20, 0x3d, 0x20, 0x70, 0x61, 0x72, 0x73, 0x65, 0x49, 0x6e, 0x74, 0x28, 0x63,
//   0x6f, 0x6c, 0x6f, 0x72, 0x2e, 0x73, 0x75, 0x62, 0x73, 0x74, 0x72, 0x28, 0x31, 0x2c, 0x32, 0x29,
//   0x2c, 0x20, 0x31, 0x36, 0x29, 0x3b, 0x0d, 0x0a, 0x20, 0x20, 0x20, 0x20, 0x20, 0x20, 0x20, 0x20,
//   0x20, 0x20, 0x20, 0x20, 0x76, 0x61, 0x72, 0x20, 0x67, 0x20, 0x3d, 0x20, 0x70, 0x61, 0x72, 0x73,
//   0x65, 0x49, 0x6e, 0x74, 0x28, 0x63, 0x6f, 0x6c, 0x6f, 0x72, 0x2e, 0x73, 0x75, 0x62, 0x73, 0x74,
//   0x72, 0x28, 0x33, 0x2c, 0x32, 0x29, 0x2c, 0x20, 0x31, 0x36, 0x29, 0x3b, 0x0d, 0x0a, 0x20, 0x20,
//   0x20, 0x20, 0x20, 0x20, 0x20, 0x20, 0x20, 0x20, 0x20, 0x20, 0x76, 0x61, 0x72, 0x20, 0x62, 0x20,
//   0x3d, 0x20, 0x70, 0x61, 0x72, 0x73, 0x65, 0x49, 0x6e, 0x74, 0x28, 0x63, 0x6f, 0x6c, 0x6f, 0x72,
//   0x2e, 0x73, 0x75, 0x62, 0x73, 0x74, 0x72, 0x28, 0x35, 0x2c, 0x32, 0x29, 0x2c, 0x20, 0x31, 0x36,
//   0x29, 0x3b, 0x0d, 0x0a, 0x20, 0x20, 0x20, 0x20, 0x20, 0x20, 0x20, 0x20, 0x20, 0x20, 0x20, 0x20,
//   0x66, 0x65, 0x74, 0x63, 0x68, 0x28, 0x27, 0x2f, 0x63, 0x6f, 0x6c, 0x6f, 0x72, 0x3f, 0x72, 0x3d,
//   0x27, 0x20, 0x2b, 0x20, 0x72, 0x20, 0x2b, 0x20, 0x27, 0x26, 0x67, 0x3d, 0x27, 0x20, 0x2b, 0x20,
//   0x67, 0x20, 0x2b, 0x20, 0x27, 0x26, 0x62, 0x3d, 0x27, 0x20, 0x2b, 0x20, 0x62, 0x29, 0x0d, 0x0a,
//   0x20, 0x20, 0x20, 0x20, 0x20, 0x20, 0x20, 0x20, 0x20, 0x20, 0x20, 0x20, 0x20, 0x20, 0x20, 0x20,
//   0x2e, 0x74, 0x68, 0x65, 0x6e, 0x28, 0x72, 0x65, 0x73, 0x70, 0x6f, 0x6e, 0x73, 0x65, 0x20, 0x3d,
//   0x3e, 0x20, 0x7b, 0x0d, 0x0a, 0x20, 0x20, 0x20, 0x20, 0x20, 0x20, 0x20, 0x20, 0x20, 0x20, 0x20,
//   0x20, 0x20, 0x20, 0x20, 0x20, 0x20, 0x20, 0x20, 0x20, 0x69, 0x66, 0x28, 0x21, 0x72, 0x65, 0x73,
//   0x70, 0x6f, 0x6e, 0x73, 0x65, 0x2e, 0x6f, 0x6b, 0x29, 0x20, 0x74, 0x68, 0x72, 0x6f, 0x77, 0x20,
//   0x6e, 0x65, 0x77, 0x20, 0x45, 0x72, 0x72, 0x6f, 0x72, 0x28, 0x27, 0xe8, 0xae, 0xbe, 0xe7, 0xbd,
//   0xae, 0xe9, 0xa2, 0x9c, 0xe8, 0x89, 0xb2, 0xe5, 0xa4, 0xb1, 0xe8, 0xb4, 0xa5, 0x27, 0x29, 0x3b,
//   0x0d, 0x0a, 0x20, 0x20, 0x20, 0x20, 0x20, 0x20, 0x20, 0x20, 0x20, 0x20, 0x20, 0x20, 0x20, 0x20,
//   0x20, 0x20, 0x20, 0x20, 0x20, 0x20, 0x73, 0x68, 0x6f, 0x77, 0x53, 0x74, 0x61, 0x74, 0x75, 0x73,
//   0x28, 0x27, 0xe9, 0xa2, 0x9c, 0xe8, 0x89, 0xb2, 0xe5, 0xb7, 0xb2, 0xe6, 0x9b, 0xb4, 0xe6, 0x96,
//   0xb0, 0x27, 0x29, 0x3b, 0x0d, 0x0a, 0x20, 0x20, 0x20, 0x20, 0x20, 0x20, 0x20, 0x20, 0x20, 0x20,
//   0x20, 0x20, 0x20, 0x20, 0x20, 0x20, 0x7d, 0x29, 0x0d, 0x0a, 0x20, 0x20, 0x20, 0x20, 0x20, 0x20,
//   0x20, 0x20, 0x20, 0x20, 0x20, 0x20, 0x20, 0x20, 0x20, 0x20, 0x2e, 0x63, 0x61, 0x74, 0x63, 0x68,
//   0x28, 0x65, 0x72, 0x72, 0x6f, 0x72, 0x20, 0x3d, 0x3e, 0x20, 0x73, 0x68, 0x6f, 0x77, 0x53, 0x74,
//   0x61, 0x74, 0x75, 0x73, 0x28, 0x27, 0xe9, 0x94, 0x99, 0xe8, 0xaf, 0xaf, 0x3a, 0x20, 0x27, 0x20,
//   0x2b, 0x20, 0x65, 0x72, 0x72, 0x6f, 0x72, 0x2e, 0x6d, 0x65, 0x73, 0x73, 0x61, 0x67, 0x65, 0x29,
//   0x29, 0x3b, 0x0d, 0x0a, 0x20, 0x20, 0x20, 0x20, 0x20, 0x20, 0x20, 0x20, 0x7d, 0x0d, 0x0a, 0x0d,
//   0x0a, 0x20, 0x20, 0x20, 0x20, 0x20, 0x20, 0x20, 0x20, 0x66, 0x75, 0x6e, 0x63, 0x74, 0x69, 0x6f,
//   0x6e, 0x20, 0x73, 0x74, 0x61, 0x72, 0x74, 0x52, 0x61, 0x69, 0x6e, 0x62, 0x6f, 0x77, 0x28, 0x29,
//   0x20, 0x7b, 0x0d, 0x0a, 0x20, 0x20, 0x20, 0x20, 0x20, 0x20, 0x20, 0x20, 0x20, 0x20, 0x20, 0x20,
//   0x66, 0x65, 0x74, 0x63, 0x68, 0x28, 0x27, 0x2f, 0x72, 0x61, 0x69, 0x6e, 0x62, 0x6f, 0x77, 0x27,
//   0x29, 0x0d, 0x0a, 0x20, 0x20, 0x20, 0x20, 0x20, 0x20, 0x20, 0x20, 0x20, 0x20, 0x20, 0x20, 0x20,
//   0x20, 0x20, 0x20, 0x2e, 0x74, 0x68, 0x65, 0x6e, 0x28, 0x72, 0x65, 0x73, 0x70, 0x6f, 0x6e, 0x73,
//   0x65, 0x20, 0x3d, 0x3e, 0x20, 0x7b, 0x0d, 0x0a, 0x20, 0x20, 0x20, 0x20, 0x20, 0x20, 0x20, 0x20,
//   0x20, 0x20, 0x20, 0x20, 0x20, 0x20, 0x20, 0x20, 0x20, 0x20, 0x20, 0x20, 0x69, 0x66, 0x28, 0x21,
//   0x72, 0x65, 0x73, 0x70, 0x6f, 0x6e, 0x73, 0x65, 0x2e, 0x6f, 0x6b, 0x29, 0x20, 0x74, 0x68, 0x72,
//   0x6f, 0x77, 0x20, 0x6e, 0x65, 0x77, 0x20, 0x45, 0x72, 0x72, 0x6f, 0x72, 0x28, 0x27, 0xe5, 0x90,
//   0xaf, 0xe5, 0x8a, 0xa8, 0xe5, 0xbd, 0xa9, 0xe8, 0x99, 0xb9, 0xe6, 0xa8, 0xa1, 0xe5, 0xbc, 0x8f,
//   0xe5, 0xa4, 0xb1, 0xe8, 0xb4, 0xa5, 0x27, 0x29, 0x3b, 0x0d, 0x0a, 0x20, 0x20, 0x20, 0x20, 0x20,
//   0x20, 0x20, 0x20, 0x20, 0x20, 0x20, 0x20, 0x20, 0x20, 0x20, 0x20, 0x20, 0x20, 0x20, 0x20, 0x73,
//   0x68, 0x6f, 0x77, 0x53, 0x74, 0x61, 0x74, 0x75, 0x73, 0x28, 0x27, 0xe5, 0xbd, 0xa9, 0xe8, 0x99,
//   0xb9, 0xe6, 0xa8, 0xa1, 0xe5, 0xbc, 0x8f, 0xe5, 0xb7, 0xb2, 0xe5, 0x90, 0xaf, 0xe5, 0x8a, 0xa8,
//   0x27, 0x29, 0x3b, 0x0d, 0x0a, 0x20, 0x20, 0x20, 0x20, 0x20, 0x20, 0x20, 0x20, 0x20, 0x20, 0x20,
//   0x20, 0x20, 0x20, 0x20, 0x20, 0x7d, 0x29, 0x0d, 0x0a, 0x20, 0x20, 0x20, 0x20, 0x20, 0x20, 0x20,
//   0x20, 0x20, 0x20, 0x20, 0x20, 0x20, 0x20, 0x20, 0x20, 0x2e, 0x63, 0x61, 0x74, 0x63, 0x68, 0x28,
//   0x65, 0x72, 0x72, 0x6f, 0x72, 0x20, 0x3d, 0x3e, 0x20, 0x73, 0x68, 0x6f, 0x77, 0x53, 0x74, 0x61,
//   0x74, 0x75, 0x73, 0x28, 0x27, 0xe9, 0x94, 0x99, 0xe8, 0xaf, 0xaf, 0x3a, 0x20, 0x27, 0x20, 0x2b,
//   0x20, 0x65, 0x72, 0x72, 0x6f, 0x72, 0x2e, 0x6d, 0x65, 0x73, 0x73, 0x61, 0x67, 0x65, 0x29, 0x29,
//   0x3b, 0x0d, 0x0a, 0x20, 0x20, 0x20, 0x20, 0x20, 0x20, 0x20, 0x20, 0x7d, 0x0d, 0x0a, 0x0d, 0x0a,
//   0x20, 0x20, 0x20, 0x20, 0x20, 0x20, 0x20, 0x20, 0x66, 0x75, 0x6e, 0x63, 0x74, 0x69, 0x6f, 0x6e,
//   0x20, 0x73, 0x65, 0x74, 0x52, 0x61, 0x6e, 0x64, 0x6f, 0x6d, 0x28, 0x29, 0x20, 0x7b, 0x0d, 0x0a,
//   0x20, 0x20, 0x20, 0x20, 0x20, 0x20, 0x20, 0x20, 0x20, 0x20, 0x20, 0x20, 0x66, 0x65, 0x74, 0x63,
//   0x68, 0x28, 0x27, 0x2f, 0x72, 0x61, 0x6e, 0x64, 0x6f, 0x6d, 0x27, 0x29, 0x0d, 0x0a, 0x20, 0x20,
//   0x20, 0x20, 0x20, 0x20, 0x20, 0x20, 0x20, 0x20, 0x20, 0x20, 0x20, 0x20, 0x20, 0x20, 0x2e, 0x74,
//   0x68, 0x65, 0x6e, 0x28, 0x72, 0x65, 0x73, 0x70, 0x6f, 0x6e, 0x73, 0x65, 0x20, 0x3d, 0x3e, 0x20,
//   0x7b, 0x0d, 0x0a, 0x20, 0x20, 0x20, 0x20, 0x20, 0x20, 0x20, 0x20, 0x20, 0x20, 0x20, 0x20, 0x20,
//   0x20, 0x20, 0x20, 0x20, 0x20, 0x20, 0x20, 0x69, 0x66, 0x28, 0x21, 0x72, 0x65, 0x73, 0x70, 0x6f,
//   0x6e, 0x73, 0x65, 0x2e, 0x6f, 0x6b, 0x29, 0x20, 0x74, 0x68, 0x72, 0x6f, 0x77, 0x20, 0x6e, 0x65,
//   0x77, 0x20, 0x45, 0x72, 0x72, 0x6f, 0x72, 0x28, 0x27, 0xe8, 0xae, 0xbe, 0xe7, 0xbd, 0xae, 0xe9,
//   0x9a, 0x8f, 0xe6, 0x9c, 0xba, 0xe9, 0xa2, 0x9c, 0xe8, 0x89, 0xb2, 0xe5, 0xa4, 0xb1, 0xe8, 0xb4,
//   0xa5, 0x27, 0x29, 0x3b, 0x0d, 0x0a, 0x20, 0x20, 0x20, 0x20, 0x20, 0x20, 0x20, 0x20, 0x20, 0x20,
//   0x20, 0x20, 0x20, 0x20, 0x20, 0x20, 0x20, 0x20, 0x20, 0x20, 0x73, 0x68, 0x6f, 0x77, 0x53, 0x74,
//   0x61, 0x74, 0x75, 0x73, 0x28, 0x27, 0xe9, 0x9a, 0x8f, 0xe6, 0x9c, 0xba, 0xe9, 0xa2, 0x9c, 0xe8,
//   0x89, 0xb2, 0xe6, 0xa8, 0xa1, 0xe5, 0xbc, 0x8f, 0xe5, 0xb7, 0xb2, 0xe5, 0x90, 0xaf, 0xe5, 0x8a,
//   0xa8, 0x27, 0x29, 0x3b, 0x0d, 0x0a, 0x20, 0x20, 0x20, 0x20, 0x20, 0x20, 0x20, 0x20, 0x20, 0x20,
//   0x20, 0x20, 0x20, 0x20, 0x20, 0x20, 0x7d, 0x29, 0x0d, 0x0a, 0x20, 0x20, 0x20, 0x20, 0x20, 0x20,
//   0x20, 0x20, 0x20, 0x20, 0x20, 0x20, 0x20, 0x20, 0x20, 0x20, 0x2e, 0x63, 0x61, 0x74, 0x63, 0x68,
//   0x28, 0x65, 0x72, 0x72, 0x6f, 0x72, 0x20, 0x3d, 0x3e, 0x20, 0x73, 0x68, 0x6f, 0x77, 0x53, 0x74,
//   0x61, 0x74, 0x75, 0x73, 0x28, 0x27, 0xe9, 0x94, 0x99, 0xe8, 0xaf, 0xaf, 0x3a, 0x20, 0x27, 0x20,
//   0x2b, 0x20, 0x65, 0x72, 0x72, 0x6f, 0x72, 0x2e, 0x6d, 0x65, 0x73, 0x73, 0x61, 0x67, 0x65, 0x29,
//   0x29, 0x3b, 0x0d, 0x0a, 0x20, 0x20, 0x20, 0x20, 0x20, 0x20, 0x20, 0x20, 0x7d, 0x0d, 0x0a, 0x0d,
//   0x0a, 0x20, 0x20, 0x20, 0x20, 0x20, 0x20, 0x20, 0x20, 0x66, 0x75, 0x6e, 0x63, 0x74, 0x69, 0x6f,
//   0x6e, 0x20, 0x73, 0x68, 0x6f, 0x77, 0x53, 0x74, 0x61, 0x74, 0x75, 0x73, 0x28, 0x6d, 0x65, 0x73,
//   0x73, 0x61, 0x67, 0x65, 0x29, 0x20, 0x7b, 0x0d, 0x0a, 0x20, 0x20, 0x20, 0x20, 0x20, 0x20, 0x20,
//   0x20, 0x20, 0x20, 0x20, 0x20, 0x63, 0x6f, 0x6e, 0x73, 0x74, 0x20, 0x73, 0x74, 0x61, 0x74, 0x75,
//   0x73, 0x20, 0x3d, 0x20, 0x64, 0x6f, 0x63, 0x75, 0x6d, 0x65, 0x6e, 0x74, 0x2e, 0x67, 0x65, 0x74,
//   0x45, 0x6c, 0x65, 0x6d, 0x65, 0x6e, 0x74, 0x42, 0x79, 0x49, 0x64, 0x28, 0x27, 0x73, 0x74, 0x61,
//   0x74, 0x75, 0x73, 0x27, 0x29, 0x3b, 0x0d, 0x0a, 0x20, 0x20, 0x20, 0x20, 0x20, 0x20, 0x20, 0x20,
//   0x20, 0x20, 0x20, 0x20, 0x73, 0x74, 0x61, 0x74, 0x75, 0x73, 0x2e, 0x74, 0x65, 0x78, 0x74, 0x43,
//   0x6f, 0x6e, 0x74, 0x65, 0x6e, 0x74, 0x20, 0x3d, 0x20, 0x6d, 0x65, 0x73, 0x73, 0x61, 0x67, 0x65,
//   0x3b, 0x0d, 0x0a, 0x20, 0x20, 0x20, 0x20, 0x20, 0x20, 0x20, 0x20, 0x20, 0x20, 0x20, 0x20, 0x73,
//   0x65, 0x74, 0x54, 0x69, 0x6d, 0x65, 0x6f, 0x75, 0x74, 0x28, 0x28, 0x29, 0x20, 0x3d, 0x3e, 0x20,
//   0x73, 0x74, 0x61, 0x74, 0x75, 0x73, 0x2e, 0x74, 0x65, 0x78, 0x74, 0x43, 0x6f, 0x6e, 0x74, 0x65,
//   0x6e, 0x74, 0x20, 0x3d, 0x20, 0x27, 0x27, 0x2c, 0x20, 0x33, 0x30, 0x30, 0x30, 0x29, 0x3b, 0x0d,
//   0x0a, 0x20, 0x20, 0x20, 0x20, 0x20, 0x20, 0x20, 0x20, 0x7d, 0x0d, 0x0a, 0x20, 0x20, 0x20, 0x20,
//   0x3c, 0x2f, 0x73, 0x63, 0x72, 0x69, 0x70, 0x74, 0x3e, 0x0d, 0x0a, 0x20, 0x20, 0x20, 0x20, 0x3c,
//   0x2f, 0x62, 0x6f, 0x64, 0x79, 0x3e, 0x0d, 0x0a, 0x3c, 0x2f, 0x68, 0x74, 0x6d, 0x6c, 0x3e,
// };

static int get_query_param(const char* path, const char* param_name, char* value, int max_len) {
  const char* start;
  const char* end;

  start = strstr(path, param_name);
  if(!start) {
      return -1;
  }

  start += strlen(param_name);

  end = strchr(start, '&');
  if(!end) {
      end = start + strlen(start);
  }

  size_t len = end - start;
  if(len >= max_len) {
      len = max_len - 1;
  }

  memcpy(value, start, len);
  value[len] = '\0';

  return len;
}

// void http_request_handler(int socket, http_request_t *request) {
//   printf("Received HTTP %s request for %s\r\n",
//          request->method == HTTP_GET ? "GET" : "POST",
//          request->path);

//   if (strcmp(request->path, "/") == 0) {
//       http_send_response(socket, "200 OK", "text/html", index);
//   } else if (strcmp(request->path, "/status") == 0) {
//       char response[256];
//       snprintf(response, sizeof(response),
//               "{\"status\":\"running\",\"uptime\":%lu}",
//               HAL_GetTick());
//       http_send_response(socket, "200 OK", "application/json", response);
//   }
//   else {
//       const char *response = "<html><body><h1>404 Not Found</h1></body></html>";
//       http_send_response(socket, "404 Not Found", "text/html", response);
//   }
// }

// /rainbow
void rainbow_handler(int socket, http_request_t *request) {
  printf("Setting rainbow mode\r\n");
  http_send_response(socket, "200 OK", "text/plain", "OK");
}

// /random
void random_handler(int socket, http_request_t *request) {
  printf("Setting random mode\r\n");

  http_send_response(socket, "200 OK", "text/plain", "OK");
}

// /brightness
void brightness_handler(int socket, http_request_t *request) {
  char value_str[16] = {0};
  int value_len = get_query_param(request->path, "?value=", value_str, sizeof(value_str));
  printf("Brightness value: %s\r\n", value_str);
  if (value_str) {
    int value = atoi(value_str);
    printf("Setting brightness: %d\r\n", value);
    http_send_response(socket, "200 OK", "text/plain", "OK");
  } else {
    http_send_response(socket, "400 Bad Request", "text/plain", "Missing brightness value");
  }
}

// /color
void color_handler(int socket, http_request_t *request) {
  char r_str[16] = {0};
  char g_str[16] = {0};
  char b_str[16] = {0};

  int r_len = get_query_param(request->path, "?r=", r_str, sizeof(r_str));
  int g_len = get_query_param(request->path, "&g=", g_str, sizeof(g_str));
  int b_len = get_query_param(request->path, "&b=", b_str, sizeof(b_str));
  printf("r: %s, g: %s, b: %s\r\n", r_str, g_str, b_str);

  if (r_str && g_str && b_str) {
    int r = atoi(r_str);
    int g = atoi(g_str);
    int b = atoi(b_str);

    printf("Setting color: R=%d, G=%d, B=%d\r\n", r, g, b);

    http_send_response(socket, "200 OK", "text/plain", "OK");
  } else {
    http_send_response(socket, "400 Bad Request", "text/plain", "Missing RGB parameters");
  }
}

// FIL file;                       /* 文件对象 */
// FRESULT f_res;                  /* 文件操作结果 */
// UINT fnum;                      /* 文件成功读写数量 */
// void StartSdTask(void* argument)
// {

//   /* USER CODE BEGIN 5 */
//   printf("\r\n****** FatFs Example ******\r\n\r\n");
// FRESULT f_res;
//   f_res = f_mount(&fs, "0:", 1);

//   // 没有报错
//   if (f_res != FR_OK)
//   {
//     // delete Task
//     osThreadTerminate(NULL);
//   }
//   f_res = f_open(&file, "0:FatFs STM32cube.txt", FA_CREATE_ALWAYS | FA_WRITE);
//   if(f_res == FR_OK)
//   {
//     f_res = f_write(&file, WriteBuffer, sizeof(WriteBuffer), &fnum);
//     if(f_res == FR_OK)
//     {
//       printf(" write file sucess!!! (%d)\n", fnum);
//       printf(" write Data : %s\r\n", WriteBuffer);
//     }else{
//       printf(" write file error : %d\r\n", f_res);
//     }
//     f_close(&file);
//   }else{
//     printf(" open file error : %d\r\n", f_res);
//   }
//   printf("\r\n****** Read data from the text files ******\r\n");
//   f_res = f_open(&file, "0:FatFs STM32cube.txt", FA_OPEN_EXISTING | FA_READ);
//   if(f_res == FR_OK){
//     f_res = f_read(&file, ReadBuffer, sizeof(ReadBuffer), &fnum);
//     if(f_res == FR_OK){
//       printf("read sucess!!! (%d)\n", fnum);
//       printf("read Data : %s\r\n", ReadBuffer);
//     }else{
//       printf(" read error!!! %d\r\n", f_res);
//     }
//   }else{
//     printf(" open file error : %d\r\n", f_res);
//   }
//   f_close(&file);
//   f_mount(NULL, "0:", 1);
//   /* Infinite loop */
//   for(;;)
//   {
//     osDelay(1000);
//   }
//   /* USER CODE END 5 */
// }

/* USER CODE END Application */

/************************ (C) COPYRIGHT STMicroelectronics *****END OF FILE****/
